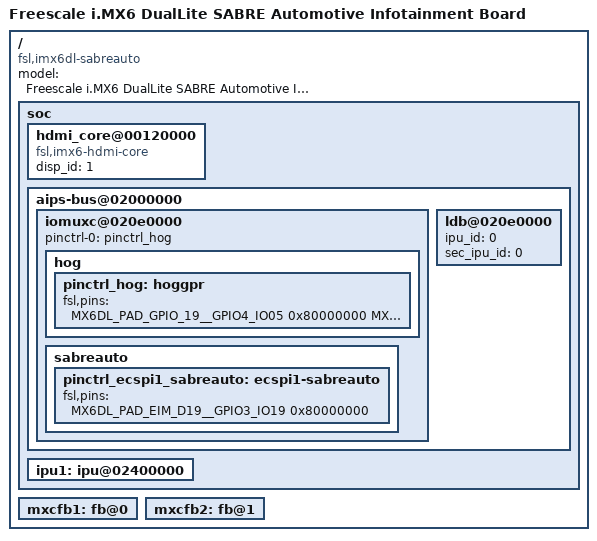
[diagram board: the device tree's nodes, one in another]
/*
 * Copyright 2013 Freescale Semiconductor, Inc.
 *
 * This program is free software; you can redistribute it and/or modify
 * it under the terms of the GNU General Public License version 2 as
 * published by the Free Software Foundation.
 *
 */

/dts-v1/;
#include "imx6dl.dtsi"
#include "imx6qdl-sabreauto.dtsi"

/ {
	model = "Freescale i.MX6 DualLite SABRE Automotive Infotainment Board";
	compatible = "fsl,imx6dl-sabreauto", "fsl,imx6dl";

	soc {
		hdmi_core@00120000 {
			compatible = "fsl,imx6-hdmi-core";
			disp_id = <1>;
			status = "okay";
		};

		aips-bus@02000000 { /* AIPS1 */
			iomuxc@020e0000 {
				pinctrl-names = "default";
				pinctrl-0 = <&pinctrl_hog>;

				hog {
					pinctrl_hog: hoggpr {
						fsl,pins = <
							/* RGMII Phy Interrupt */
							MX6DL_PAD_GPIO_19__GPIO4_IO05 0x80000000
							MX6DL_PAD_EIM_EB0__GPIO2_IO28 0x80000000
						>;
					};
				};

				sabreauto {
					pinctrl_ecspi1_sabreauto: ecspi1-sabreauto {
						fsl,pins = <
							MX6DL_PAD_EIM_D19__GPIO3_IO19 0x80000000
						>;
					};
				};
			};

			ldb@020e0000 {
				ipu_id = <0>;
				sec_ipu_id = <0>;
			};
		};

		ipu1: ipu@02400000 { /* IPU1 */
			status = "okay";
		};
	};

	mxcfb1: fb@0 {
		status = "okay";
	};

	mxcfb2: fb@1 {
		status = "okay";
	};
};
